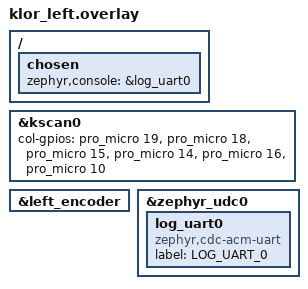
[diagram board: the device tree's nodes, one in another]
/*
 * Copyright (c) 2022 GEIST
 *
 * SPDX-License-Identifier: MIT
 */

#include "klor.dtsi"

&kscan0 {
	col-gpios
		= <&pro_micro 19 GPIO_ACTIVE_HIGH>
		, <&pro_micro 18 GPIO_ACTIVE_HIGH>
		, <&pro_micro 15 GPIO_ACTIVE_HIGH>
		, <&pro_micro 14 GPIO_ACTIVE_HIGH>
		, <&pro_micro 16 GPIO_ACTIVE_HIGH>
		, <&pro_micro 10 GPIO_ACTIVE_HIGH>
		;
};

&left_encoder {
	status = "okay";
};

/* Second CDC-ACM UART, separate from Studio's RPC channel (snippet
 * studio-rpc-usb-uart, see build.yaml), dedicated as the console for
 * CONFIG_ZMK_USB_LOGGING (klor_left.conf). Both need their own UART —
 * they can't share one. */
&zephyr_udc0 {
	log_uart0: log_uart0 {
		compatible = "zephyr,cdc-acm-uart";
		label = "LOG_UART_0";
	};
};

/ {
	chosen {
		zephyr,console = &log_uart0;
	};
};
